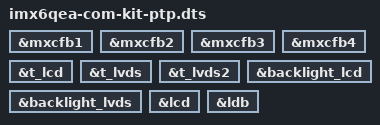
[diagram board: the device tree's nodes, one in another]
/*
 * Copyright 2012 Freescale Semiconductor, Inc.
 * Copyright 2011 Linaro Ltd.
 *
 * The code contained herein is licensed under the GNU General Public
 * License. You may obtain a copy of the GNU General Public License
 * Version 2 or later at the following locations:
 *
 * http://www.opensource.org/licenses/gpl-license.html
 * http://www.gnu.org/copyleft/gpl.html
 */

#include "imx6qea-com-kit.dts"

&mxcfb1 {
	status = "okay";
};
&mxcfb2 {
        status = "okay";
};
&mxcfb3 {
        status = "okay";
};
&mxcfb4 {
        status = "okay";
};
&t_lcd {
        status = "okay";
};
&t_lvds {
        status = "okay";
};
&t_lvds2 {
        status = "okay";
};
&backlight_lcd {
        status = "okay";
};
&backlight_lvds {
        status = "okay";
};
&lcd {
        status = "okay";
};
&ldb {
        status = "okay";
};
